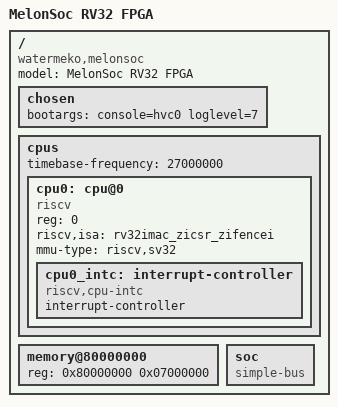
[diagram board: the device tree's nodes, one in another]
/dts-v1/;

/ {
	#address-cells = <1>;
	#size-cells = <1>;
	compatible = "watermeko,melonsoc";
	model = "MelonSoc RV32 FPGA";

	chosen {
		bootargs = "console=hvc0 loglevel=7";
	};

	cpus {
		#address-cells = <1>;
		#size-cells = <0>;
		timebase-frequency = <27000000>;

		cpu0: cpu@0 {
			compatible = "riscv";
			device_type = "cpu";
			reg = <0>;
			riscv,isa = "rv32imac_zicsr_zifencei";
			mmu-type = "riscv,sv32";
			status = "okay";

			cpu0_intc: interrupt-controller {
				#interrupt-cells = <1>;
				compatible = "riscv,cpu-intc";
				interrupt-controller;
			};
		};
	};

	memory@80000000 {
		device_type = "memory";
		reg = <0x80000000 0x07000000>;
	};

	soc {
		#address-cells = <1>;
		#size-cells = <1>;
		compatible = "simple-bus";
		ranges;
	};
};
